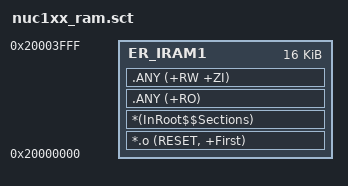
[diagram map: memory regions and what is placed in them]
; *************************************************************
; *** Scatter-Loading Description File generated by uVision ***
; *************************************************************

LR_IRAM1 0x20000000 0x00004000  {    ; load region size_region
  ER_IRAM1 0x20000000 0x00004000  {  ; load address = execution address
   *.o (RESET, +First)
   *(InRoot$$Sections)
   .ANY (+RO)

   .ANY (+RW +ZI)                    ; RW data
  }
}

